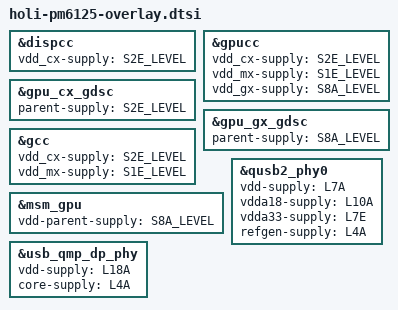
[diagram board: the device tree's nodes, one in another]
&dispcc {
	vdd_cx-supply = <&S2E_LEVEL>; /* VDD_CX_LEVEL */
};

&gpucc {
	vdd_cx-supply = <&S2E_LEVEL>; /* VDD_CX_LEVEL */
	vdd_mx-supply = <&S1E_LEVEL>; /* VDD_MX_LEVEL */
	vdd_gx-supply = <&S8A_LEVEL>; /* VDD_GFX_LEVEL */
};

&gpu_cx_gdsc {
	parent-supply = <&S2E_LEVEL>; /* VDD_CX_LEVEL */
};

&gpu_gx_gdsc {
	parent-supply = <&S8A_LEVEL>; /* VDD_GFX_LEVEL */
};

&gcc {
	vdd_cx-supply = <&S2E_LEVEL>; /* VDD_CX_LEVEL */
	vdd_mx-supply = <&S1E_LEVEL>; /* VDD_MX_LEVEL */
};

&msm_gpu {
	vdd-parent-supply = <&S8A_LEVEL>; /* VDD_GFX_LEVEL */
};

&qusb2_phy0 {
	vdd-supply = <&L7A>;
	vdda18-supply = <&L10A>;
	vdda33-supply = <&L7E>;
	refgen-supply = <&L4A>;
};

&usb_qmp_dp_phy {
	vdd-supply = <&L18A>;
	core-supply = <&L4A>;
};
